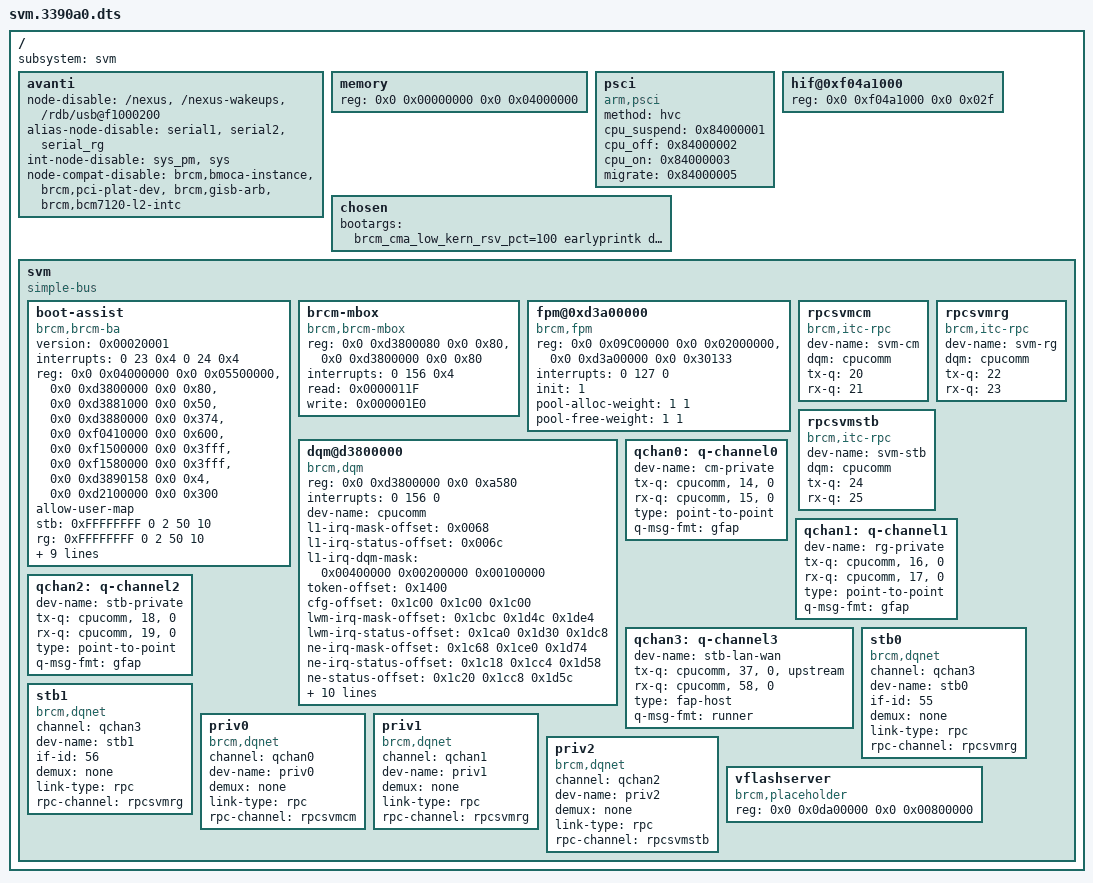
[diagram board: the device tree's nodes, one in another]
/dts-v1/;

/ {
	subsystem = "svm";
	#address-cells = <0x2>;
	#size-cells = <0x2>;

	/* This node will "tweak" the device tree as provided by the boot loader.
	* Disabled nodes will still be present, but associated driver will not load,
	* and resources will not be provided via hypervisor
	*
	* Disable by node name:
	*	nexus - this is needed only in the STB vm
	*	nexus-wakeups - this is needed only in STB VM
	*	usb@f1000200 - only 1 USB enabled for SVM, other used in RG VM
	* Disable by alias name:
	*	serial1 - Used by STB VM
	*	serial2 - not used
	*	serial_rg - Used by RG VM
	* Disable l2-intc by name:
	*	sys_pm - Used for power management... STB VM, but does not apply to 3390
	*	sys - Used by GISB arb driver.. overlaps w/ nexus interrupts. TBD
	* Disable by compatible string:
	*	bmoca-instance - Used by RG VM (moca)
	*	pc-plat-dev - Used by RG VM (pcie)
	*	gisb-arb - Used by GISB arb driver... overlaps w/ nexus interrupts. TBD
	*	bcm7120-l2-intc - Not used yet... STB VM? TBD
	*/
	avanti {
		node-disable = "/nexus", "/nexus-wakeups","/rdb/usb@f1000200";
		alias-node-disable = "serial1", "serial2", "serial_rg";
		int-node-disable = "sys_pm", "sys";
		node-compat-disable = "brcm,bmoca-instance", "brcm,pci-plat-dev", "brcm,gisb-arb", "brcm,bcm7120-l2-intc";
	};

	memory {
		#address-cells = <0x1>;
		#size-cells = <0x1>;
		device_type = "memory";
		reg = <0x0 0x00000000 0x0 0x04000000>;
	};

        psci {
                compatible      = "arm,psci";
                method          = "hvc";
                cpu_suspend     = <0x84000001>;
                cpu_off         = <0x84000002>;
                cpu_on          = <0x84000003>;
                migrate         = <0x84000005>;
        };

	hif@0xf04a1000 {
		reg = <0x0 0xf04a1000 0x0 0x02f>;
	};

	chosen {
		//bootargs = "brcm_cma_low_kern_rsv_pct=100 earlyprintk debug";
		bootargs = "brcm_cma_low_kern_rsv_pct=100 earlyprintk debug ubi.mtd=flash1.svm0 root=ubi0:rootfs rootfstype=ubifs platformboot";
	};

	svm {
		compatible = "simple-bus";
		#address-cells = <0x2>;
		#size-cells = <0x2>;
		ranges;

		//Boot Assist
		boot-assist {
			compatible = "brcm,brcm-ba";
			version = < 0x00020001 >;
			interrupts = <0 23 0x4 0 24 0x4>;
			reg = <0x0 0x04000000 0x0 0x05500000>, //Memory Region
			      <0x0 0xd3800000 0x0 0x80>, //CPU_COMM_REGS_CPUC
			      <0x0 0xd3881000 0x0 0x50>, //RG_TOP_CTRL
			      <0x0 0xd3880000 0x0 0x374>, //CM_TOP_CTRL
			      <0x0 0xf0410000 0x0 0x600>, //AON_CTRL
			      <0x0 0xf1500000 0x0 0x3fff>, //MEMC_0
			      <0x0 0xf1580000 0x0 0x3fff>, //MEMC_1
			      <0x0 0xd3890158 0x0 0x4>, //JTAG_OTP_UB:STATUS_16
			      <0x0 0xd2100000 0x0 0x300>; //LEAP_CTRL: Control registers
			reg-names = "mem", "cpuc", "rgtop", "cmtop", "aon", "mc0", "mc1", "otp", "leap";
			allow-user-map;
			stb = < 0xFFFFFFFF 0 2 50 10 >; //start, size, # cpu, priority, latency
			rg = < 0xFFFFFFFF 0 2 50 10 >; //start, size, # cpu, priority, latency
			tp1 = < 0xFFFFFFFF 0 >; //start, size
			cm_xfer = < 0x09410000 0x20000 0x2 >; //start, size, count
			leap = < 0x07F00000 0x100000>; //start, size
			cm_atw = < 0x0 0x04000000 0x4000000 0x0 0x4807FFFC 0x0 0x0 0x0 >; //index, start, size, destination, client0-3
			cm_dsp_atw = < 0x1 0x08000000 0x200000 0x7e00000 0x4804FFFC 0x0 0x0 0x0 >; //index, start, size, destination, client0-3
			cm_boot_atw = < 0x2 0x09400000 0x10000 0x1fc00000 0x40000 0x0 0x0 0x0 >; //index, start, size, destination, client0-3
			//arc=<memc, index, ubus, exclusive, start, end, r_clients x 8, w_clients x 8>
		};

		brcm-mbox {
			compatible = "brcm,brcm-mbox";
			reg = <0x0 0xd3800080 0x0 0x80>,  //MBOX_CPUC
				  <0x0 0xd3800000 0x0 0x80>;  //CPU_COMM_REGS_CPUC
			interrupts = <0 156 0x4>;
			read = < 0x0000011F >; /* 0,1,2,3,4,8 */
			write = < 0x000001E0 >; /* 5, 6, 7, 8 */
		};

		fpm@0xd3a00000 {
			compatible = "brcm,fpm";
			reg = <0x0 0x09C00000 0x0 0x02000000>,	/* Free Pool 0	*/
			      <0x0 0xd3a00000 0x0 0x30133>;	/* Registers	*/
//			      <0x0 0x86000000 0x0 0x02000000>;	/* Free Pool 1	*/
//			      <0x0 0x00000000 0x0 0x0>,		/* Free Pool 1	*/
//			      <0x0 0xd7e00000 0x0 0x1000>,	/* UBUS capture engines 0 */
//			      <0x0 0xd3e00000 0x0 0x1000>;	/* UBUS capture engines 1 */
			interrupts = <0 127 0>;
			init = <1>;
			pool-alloc-weight	= <1 1>;
			pool-free-weight	= <1 1>;
		};

		dqm@d3800000 {
			compatible = "brcm,dqm";
			reg = <0x0 0xd3800000 0x0 0xa580>;
			interrupts = <0 156 0>;

			dev-name = "cpucomm";

			l1-irq-mask-offset	= <0x0068>;
			l1-irq-status-offset	= <0x006c>;
			l1-irq-dqm-mask		= <0x00400000 0x00200000 0x00100000>;
			token-offset		= <0x1400>;

			cfg-offset		= <0x1c00 0x1c00 0x1c00>;
			lwm-irq-mask-offset	= <0x1cbc 0x1d4c 0x1de4>;
			lwm-irq-status-offset	= <0x1ca0 0x1d30 0x1dc8>;
			ne-irq-mask-offset	= <0x1c68 0x1ce0 0x1d74>;
			ne-irq-status-offset	= <0x1c18 0x1cc4 0x1d58>;
			ne-status-offset	= <0x1c20 0x1cc8 0x1d5c>;
			fpm-alloc-offset	= <0x1df0 0x1df0 0x1df0>;	/* bug in 3390a0 requires write to prior reg */

			q-ctl-base-offset	= <0x8000 0x8400 0x8800>;
			q-data-base-offset	= <0x9000 0x9400 0x9800>;
			q-status-base-offset	= <0x7400 0x7480 0x7500>;
			q-mib-base-offset       = <0xa000 0xa200 0xa400>;

			q-count			= <96>;
			cfg-qsm			= <1>;
			qsm-size		= <0x3000>;
			#qsm-alloc-cells	= <4>;
			/* set all Q's to offload due to chip bug in A0 where non-offload doesn't work */
			/* do not use 3rd bank (Q #'s 64-95) due to chip bug in some A0 mask and other register reads & writes */
			/* limit all Q's so that offload will not occur due to chip bug in A0 */
						  /* Q #, # words/element, # elements (depth), offload(1)/non-offload(0) */
			qsm-allocation		= < 0   4  7     1		/* RPC RG-->STB				*/
						    1   4  7     1		/* RPC RG<--STB				*/
						    2   4  7     1		/* RPC RG-->CM				*/
						    3   4  7     1		/* RPC RG<--CM				*/
						    6   4  7     1		/* RPC STB-->CM				*/
						    7   4  7     1		/* RPC STB<--CM				*/
						    8   4  7     1		/* RPC DECT-->CM			*/
						    9   4  7     1		/* RPC DECT<--CM			*/
						    10  2  15    1		/* Private Network DECT-->CM		*/
						    11  2  15    1		/* Private Network DECT<--CM		*/
						    14  2  15    1		/* Private Network SVM (bridge)-->CM	*/
						    15  2  15    1		/* Private Network SVM (bridge)<--CM	*/
						    16  2  15    1		/* Private Network SVM (bridge)-->RG	*/
						    17  2  15    1		/* Private Network SVM (bridge)<--RG	*/
						    18  2  15    1		/* Private Network SVM (bridge)-->STB	*/
						    19  2  15    1		/* Private Network SVM (bridge)<--STB	*/
						    20  4  7     1		/* RPC SVM-->CM				*/
						    21  4  7     1		/* RPC SVM<--CM				*/
						    22  4  7     1		/* RPC SVM-->RG				*/
						    23  4  7     1		/* RPC SVM<--RG				*/
						    24  4  7     1		/* RPC SVM-->STB			*/
						    25  4  7     1		/* RPC SVM<--STB			*/
						    32  2  15    1		/* RG DS Forward	(RG-->Runner)	*/
						    33  2  15    1		/* WiFi US Forward	(WiFi-->Runner)	*/
						    34  2  15    1		/* RG DS Egress		(RG-->Runner)	*/
						    35  2  15    1		/* RG US Egress		(RG-->Runner)	*/
						    36  2  15    1		/* STB DS Forward	(STB-->Runner)	*/
						    37  2  15    1		/* STB US Forward	(STB-->Runner)	*/
						    38  2  15    1		/* STB DS Egress	(STB-->Runner)	*/
						    39  2  15    1		/* STB US Egress	(STB-->Runner)	*/
						    40  2  15    1		/* DFAP DS Forward	(DFAP-->Runner)	*/
						    41  2  15    1		/* DFAP US Forward	(DFAP-->Runner)	*/
						    42  2  15    1		/* DFAP DS Egress	(DFAP-->Runner)	*/
						    43  2  15    1		/* DFAP US Egress	(DFAP-->Runner)	*/
						    44  2  15    1		/* Viper DS Forward	(DFAP-->Runner)	*/
						    45  2  15    1		/* Viper US Forward	(DFAP-->Runner)	*/
						    46  2  15    1		/* Viper DS Egress	(DFAP-->Runner)	*/
						    47  2  15    1		/* Viper US Egress	(DFAP-->Runner)	*/
						    48  4  7     1		/* RG Exception 0	(Runner-->RG)	*/
						    49  4  7     1		/* RG Exception 1	(Runner-->RG)	*/
						    50  4  7     1		/* RG Exception 2	(Runner-->RG)	*/
						    51  4  7     1		/* RG Exception 3	(Runner-->RG)	*/
						    52  4  7     1		/* RG Exception 4	(Runner-->RG)	*/
						    53  4  7     1		/* RG Exception 5	(Runner-->RG)	*/
						    54  4  7     1		/* RG Exception 6	(Runner-->RG)	*/
						    55  4  7     1		/* RG Exception 7	(Runner-->RG)	*/
						    56  4  7     1		/* WiFi 0 Rx		(Runner-->WiFi)	*/
						    57  4  7     1		/* WiFi 1 Rx		(Runner-->WiFi)	*/
						    58  4  7     1		/* STB 0 Rx		(Runner-->STB)	*/
						    59  4  7     1 >; 		/* STB 1 Rx		(Runner-->STB)	*/
		};

		rpcsvmcm: rpcsvmcm {
			compatible = "brcm,itc-rpc";
			dev-name = "svm-cm";
			dqm = "cpucomm";
			tx-q = <20>;
			rx-q = <21>;
		};

		rpcsvmrg: rpcsvmrg {
			compatible = "brcm,itc-rpc";
			dev-name = "svm-rg";
			dqm = "cpucomm";
			tx-q = <22>;
			rx-q = <23>;
		};

		rpcsvmstb: rpcsvmstb {
			compatible = "brcm,itc-rpc";
			dev-name = "svm-stb";
			dqm = "cpucomm";
			tx-q = <24>;
			rx-q = <25>;
		};

		qchan0: q-channel0 {
			dev-name = "cm-private";

			#tx-q-cells = <3>;
			/*	DQM device,	Q#,	Priority	US/DS				*/
			tx-q =	"cpucomm",	"14",	"0";				/* SVM-->CM	*/
			#rx-q-cells = <3>;
			/*	DQM device,	Q#,	Priority					*/
			rx-q =	"cpucomm",	"15",	"0";				/* CM-->SVM	*/

			type = "point-to-point";
			q-msg-fmt = "gfap";
		};

		qchan1: q-channel1 {
			dev-name = "rg-private";

			#tx-q-cells = <3>;
			/*	DQM device,	Q#,	Priority	US/DS				*/
			tx-q =	"cpucomm",	"16",	"0";				/* SVM-->RG	*/
			#rx-q-cells = <3>;
			/*	DQM device,	Q#,	Priority					*/
			rx-q =	"cpucomm",	"17",	"0";				/* RG-->SVM	*/

			type = "point-to-point";
			q-msg-fmt = "gfap";
		};

		qchan2: q-channel2 {
			dev-name = "stb-private";

			#tx-q-cells = <3>;
			/*	DQM device,	Q#,	Priority	US/DS				*/
			tx-q =	"cpucomm",	"18",	"0";				/* SVM-->STB	*/
			#rx-q-cells = <3>;
			/*	DQM device,	Q#,	Priority					*/
			rx-q =	"cpucomm",	"19",	"0";				/* STB-->SVM	*/

			type = "point-to-point";
			q-msg-fmt = "gfap";
		};

		qchan3: q-channel3 {
			dev-name = "stb-lan-wan";

			#tx-q-cells = <4>;
			/*	DQM device,	Q#,	Priority	US/DS					*/
			tx-q =	"cpucomm",	"37",	"0",		"upstream";	/* STB upstream forward	*/
			#rx-q-cells = <3>;
			/*	DQM device,	Q#,	Priority						*/
			rx-q =	"cpucomm",	"58",	"0";				/* Runner-->STB		*/

			type = "fap-host";
			q-msg-fmt = "runner";
		};

		stb0 { /* STB routed */
			compatible = "brcm,dqnet";
			channel = <&qchan3>;
			dev-name = "stb0";
			if-id = <55>;		/* rdpa_if_ssid14 */
			demux = "none";
			link-type = "rpc";
			rpc-channel = <&rpcsvmrg>;
		};

		stb1 { /* STB bridged */
			compatible = "brcm,dqnet";
			channel = <&qchan3>;
			dev-name = "stb1";
			if-id = <56>;		/* rdpa_if_ssid15 */
			demux = "none";
			link-type = "rpc";
			rpc-channel = <&rpcsvmrg>;
		};

		priv0 { /* SVM <--> CM private */
			compatible = "brcm,dqnet";
			channel = <&qchan0>;
			dev-name = "priv0";
			demux = "none";
			link-type = "rpc";
			rpc-channel = <&rpcsvmcm>;
		};

		priv1 { /* SVM <--> RG private */
			compatible = "brcm,dqnet";
			channel = <&qchan1>;
			dev-name = "priv1";
			demux = "none";
			link-type = "rpc";
			rpc-channel = <&rpcsvmrg>;
		};

		priv2 { /* SVM <--> STB private */
			compatible = "brcm,dqnet";
			channel = <&qchan2>;
			dev-name = "priv2";
			demux = "none";
			link-type = "rpc";
			rpc-channel = <&rpcsvmstb>;
		};

		vflashserver {
			compatible = "brcm,placeholder";
			reg = <0x0 0x0da00000 0x0 0x00800000>;
		};
	};
};
